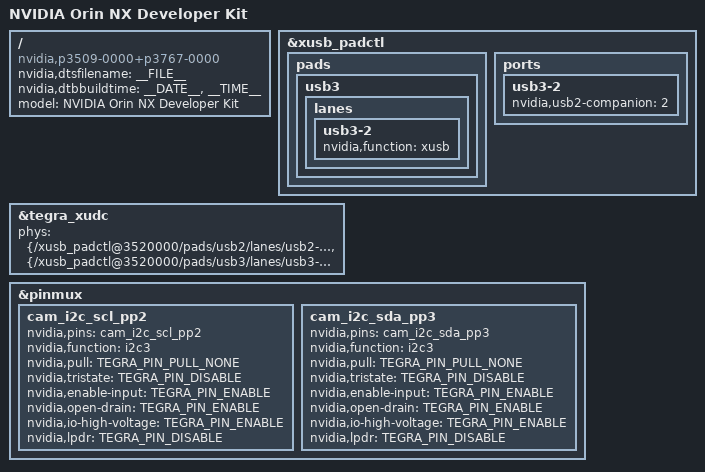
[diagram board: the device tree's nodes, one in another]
/*
 * Top level DTS file for CVM:P3767-0000 and CVB:P3509-a02-0000.
 *
 * Copyright (c) 2021-2022, NVIDIA CORPORATION.  All rights reserved.
 *
 * This program is free software; you can redistribute it and/or modify
 * it under the terms of the GNU General Public License as published by
 * the Free Software Foundation; version 2 of the License.
 *
 * This program is distributed in the hope that it will be useful, but WITHOUT
 * ANY WARRANTY; without even the implied warranty of MERCHANTABILITY or
 * FITNESS FOR A PARTICULAR PURPOSE.  See the GNU General Public License for
 * more details.
 */

/dts-v1/;
#include "tegra234-dcb-p3767-0000-hdmi.dtsi"
#include <tegra234-soc/mods-simple-bus.dtsi>
#include <t234-common-cvm/tegra234-thermal.dtsi>
#include <t234-common-cvm/tegra234-cpuidle.dtsi>
#include <t234-common-cvm/tegra234-thermal-cooling.dtsi>
#include <t234-common-cvm/tegra234-thermal-userspace-alert.dtsi>
#include "cvm/tegra234-p3767-0000.dtsi"
#include "cvb/tegra234-p3509-a02.dtsi"

/ {
	nvidia,dtsfilename = __FILE__;
	nvidia,dtbbuildtime = __DATE__, __TIME__;
	compatible = "nvidia,p3509-0000+p3767-0000", "nvidia,p3767-0000", "nvidia,tegra234", "nvidia,tegra23x";
	model = "NVIDIA Orin NX Developer Kit";
};


&xusb_padctl {
                        pads {
                                usb3 {
                                        lanes {
                                                usb3-2 {
                                                        nvidia,function = "xusb";
                                                        status = "okay";
                                                };
                                        };
                                };
                        };
                        ports {
                                usb3-2 {
                                        nvidia,usb2-companion = <2>;
                                        status = "okay";
                                };
                        };
};

&tegra_xudc {
                        phys = <&{/xusb_padctl@3520000/pads/usb2/lanes/usb2-0}>,
                               <&{/xusb_padctl@3520000/pads/usb3/lanes/usb3-2}>;
                        phy-names = "usb2-0", "usb3-2";
};


&pinmux {


                       cam_i2c_scl_pp2 {
                               nvidia,pins = "cam_i2c_scl_pp2";
                               nvidia,function = "i2c3";
                               nvidia,pull = <TEGRA_PIN_PULL_NONE>;
                               nvidia,tristate = <TEGRA_PIN_DISABLE>;
                               nvidia,enable-input = <TEGRA_PIN_ENABLE>;
                               nvidia,open-drain = <TEGRA_PIN_ENABLE>;
                               nvidia,io-high-voltage = <TEGRA_PIN_ENABLE>;
                               nvidia,lpdr = <TEGRA_PIN_DISABLE>;
                       };

                       cam_i2c_sda_pp3 {
                               nvidia,pins = "cam_i2c_sda_pp3";
                               nvidia,function = "i2c3";
                               nvidia,pull = <TEGRA_PIN_PULL_NONE>;
                               nvidia,tristate = <TEGRA_PIN_DISABLE>;
                               nvidia,enable-input = <TEGRA_PIN_ENABLE>;
                               nvidia,open-drain = <TEGRA_PIN_ENABLE>;
                               nvidia,io-high-voltage = <TEGRA_PIN_ENABLE>;
                               nvidia,lpdr = <TEGRA_PIN_DISABLE>;
                       };
};

